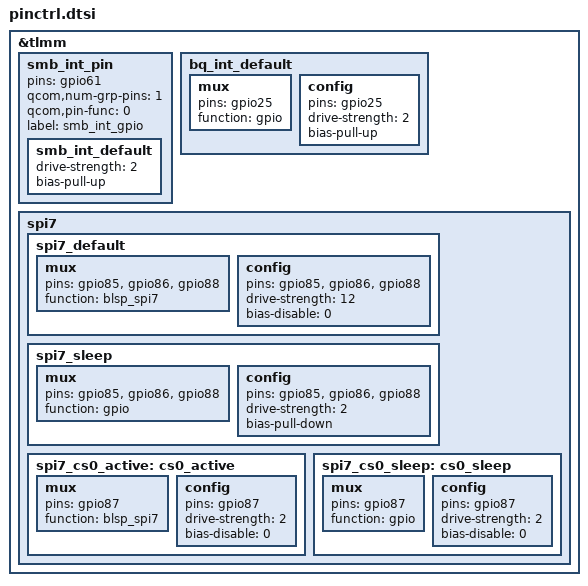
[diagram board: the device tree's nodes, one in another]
/*
 * Copyright (c) 2015-2017, The Linux Foundation. All rights reserved.
 * Copyright (C) 2018 XiaoMi, Inc.
 *
 * This program is free software; you can redistribute it and/or modify
 * it under the terms of the GNU General Public License version 2 and
 * only version 2 as published by the Free Software Foundation.
 *
 * This program is distributed in the hope that it will be useful,
 * but WITHOUT ANY WARRANTY; without even the implied warranty of
 * MERCHANTABILITY or FITNESS FOR A PARTICULAR PURPOSE.  See the
 * GNU General Public License for more details.
 */
&tlmm {
		smb_int_pin {
			pins = "gpio61";
			qcom,num-grp-pins = <1>;
			qcom,pin-func = <0>;
			label = "smb_int_gpio";
			smb_int_default: smb_int_default {
				drive-strength = <2>;	/*8 MA */
				bias-pull-up;		/* PULL UP*/
			};
		};

		bq_int_default: bq_int_default {
			mux {
				pins = "gpio25";
				function ="gpio";
			};
			config {
				pins = "gpio25";
				drive-strength = <2>; /* 2 MA */
				bias-pull-up;
				/* PULL UP*/
				};
		};

		spi7 {
			spi7_default: spi7_default {
				/* active state */
				mux {
					/* MOSI, MISO, CLK */
					pins = "gpio85", "gpio86", "gpio88";
					function = "blsp_spi7";
				};

				config {
					pins = "gpio85", "gpio86", "gpio88";
					drive-strength = <12>; /* 12 MA */
					bias-disable = <0>; /* No PULL */
				};
			};

			spi7_sleep: spi7_sleep {
				/* suspended state */
				mux {
					/* MOSI, MISO, CLK */
					pins = "gpio85", "gpio86", "gpio88";
					function = "gpio";
				};

				config {
					pins = "gpio85", "gpio86", "gpio88";
					drive-strength = <2>; /* 2 MA */
					bias-pull-down; /* PULL Down */
				};
			};

			spi7_cs0_active: cs0_active {
				/* CS */
				mux {
					pins = "gpio87";
					function = "blsp_spi7";
				};

				config {
					pins = "gpio87";
					drive-strength = <2>;
					bias-disable = <0>;
				};
			};

			spi7_cs0_sleep: cs0_sleep {
				/* CS */
				mux {
					pins = "gpio87";
					function = "gpio";
				};

				config {
					pins = "gpio87";
					drive-strength = <2>;
					bias-disable = <0>;
				};
			};
		};
};
